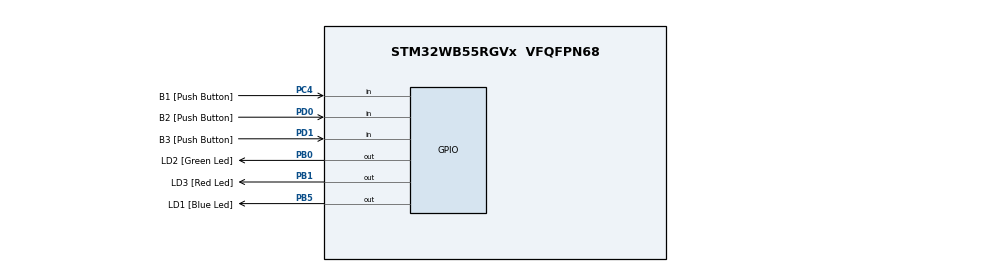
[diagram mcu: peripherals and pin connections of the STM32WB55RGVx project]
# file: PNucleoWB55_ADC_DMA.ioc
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ADC1.Channel-0\#ChannelRegularConversion=ADC_CHANNEL_VBAT
ADC1.Channel-1\#ChannelRegularConversion=ADC_CHANNEL_TEMPSENSOR
ADC1.Channel-2\#ChannelRegularConversion=ADC_CHANNEL_VREFINT
ADC1.ClockPrescaler=ADC_CLOCK_ASYNC_DIV8
ADC1.ContinuousConvMode=DISABLE
ADC1.DMAContinuousRequests=ENABLE
ADC1.EOCSelection=ADC_EOC_SINGLE_CONV
ADC1.NbrOfConversion=3
ADC1.NbrOfConversionFlag=1
ADC1.OffsetNumber-0\#ChannelRegularConversion=ADC_OFFSET_NONE
ADC1.OffsetNumber-1\#ChannelRegularConversion=ADC_OFFSET_NONE
ADC1.OffsetNumber-2\#ChannelRegularConversion=ADC_OFFSET_NONE
ADC1.Rank-0\#ChannelRegularConversion=1
ADC1.Rank-1\#ChannelRegularConversion=2
ADC1.Rank-2\#ChannelRegularConversion=3
ADC1.SamplingTime-0\#ChannelRegularConversion=ADC_SAMPLETIME_92CYCLES_5
ADC1.SamplingTime-1\#ChannelRegularConversion=ADC_SAMPLETIME_247CYCLES_5
ADC1.SamplingTime-2\#ChannelRegularConversion=ADC_SAMPLETIME_92CYCLES_5
ADC1.master=1
Dma.ADC1.0.Direction=DMA_PERIPH_TO_MEMORY
Dma.ADC1.0.EventEnable=DISABLE
Dma.ADC1.0.Instance=DMA1_Channel1
Dma.ADC1.0.MemDataAlignment=DMA_MDATAALIGN_HALFWORD
Dma.ADC1.0.MemInc=DMA_MINC_ENABLE
Dma.ADC1.0.Mode=DMA_NORMAL
Dma.ADC1.0.PeriphDataAlignment=DMA_PDATAALIGN_HALFWORD
Dma.ADC1.0.PeriphInc=DMA_PINC_DISABLE
Dma.ADC1.0.Polarity=HAL_DMAMUX_REQ_GEN_RISING
Dma.ADC1.0.Priority=DMA_PRIORITY_LOW
Dma.ADC1.0.RequestNumber=1
Dma.ADC1.0.SignalID=NONE
Dma.ADC1.0.SyncEnable=DISABLE
Dma.ADC1.0.SyncPolarity=HAL_DMAMUX_SYNC_NO_EVENT
Dma.ADC1.0.SyncRequestNumber=1
Dma.ADC1.0.SyncSignalID=NONE
Dma.Request0=ADC1
Mcu.Family=STM32WB
Mcu.Name=STM32WB55RGVx
Mcu.Package=VFQFPN68
NVIC.ADC1_IRQn=true\:0\:0\:false\:false\:true\:true\:true
NVIC.DMA1_Channel1_IRQn=true\:0\:0\:false\:false\:true\:false\:true
NVIC.PriorityGroup=NVIC_PRIORITYGROUP_4
PA13.GPIO_Label=JTMS
PA13.Mode=Trace_Asynchronous_SW
PA13.Signal=SYS_JTMS-SWDIO
PA14.GPIO_Label=JTCK
PA14.Mode=Trace_Asynchronous_SW
PA14.Signal=SYS_JTCK-SWCLK
PB0.GPIO_Label=LD2 [Green Led]
PB0.Signal=GPIO_Output
PB1.GPIO_Label=LD3 [Red Led]
PB1.Signal=GPIO_Output
PB3.GPIO_Label=JTDO
PB3.Mode=Trace_Asynchronous_SW
PB3.Signal=SYS_JTDO-SWO
PB5.GPIO_Label=LD1 [Blue Led]
PB5.Signal=GPIO_Output
PC13.Mode=SYS_WakeUp1
PC13.Signal=SYS_WKUP2
PC4.GPIO_Label=B1 [Push Button]
PC4.Signal=GPIO_Input
PD0.GPIO_Label=B2 [Push Button]
PD0.Signal=GPIO_Input
PD1.GPIO_Label=B3 [Push Button]
PD1.Signal=GPIO_Input
ProjectManager.HeapSize=0x200
ProjectManager.StackSize=0x400
ProjectManager.TargetToolchain=STM32CubeIDE
RCC.ADCFreq_Value=48000000
RCC.AHB2CLKDivider=RCC_SYSCLK_DIV2
RCC.AHBFreq_Value=64000000
RCC.APB1Freq_Value=64000000
RCC.APB1TimFreq_Value=64000000
RCC.APB2Freq_Value=64000000
RCC.APB2TimFreq_Value=64000000
RCC.APB3Freq_Value=16000000
RCC.CortexFreq_Value=64000000
RCC.HCLKFreq_Value=64000000
RCC.HSE_VALUE=32000000
RCC.HSI48_VALUE=48000000
RCC.HSI_VALUE=16000000
RCC.LSE_VALUE=32768
RCC.PLLN=32
RCC.PLLSAI1N=24
RCC.SMPSCLockSelectionVirtual=RCC_SMPSCLKSOURCE_HSI
RCC.SMPSCLockSelectionVirtualVirtual=RCC_SMPSCLKSOURCE_HSI
RCC.SYSCLKFreq_VALUE=64000000
RCC.SYSCLKSource=RCC_SYSCLKSOURCE_PLLCLK
RCC.USBFreq_Value=48000000
RCC.VCOOutputFreq_Value=128000000
VP_ADC1_TempSens_Input.Mode=IN-TempSens
VP_ADC1_Vbat_Input.Mode=IN-Vbat
VP_ADC1_Vref_Input.Mode=IN-Vrefint
board=P-NUCLEO-WB55-Nucleo

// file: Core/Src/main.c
/* USER CODE BEGIN Header */
/**
  ******************************************************************************
  * @file           : main.c
  * @brief          : Main program body
  ******************************************************************************
  * @attention
  *
  * <h2><center>&copy; Copyright (c) 2020 STMicroelectronics.
  * All rights reserved.</center></h2>
  *
  * This software component is licensed by ST under BSD 3-Clause license,
  * the "License"; You may not use this file except in compliance with the
  * License. You may obtain a copy of the License at:
  *                        opensource.org/licenses/BSD-3-Clause
  *
  ******************************************************************************
  */
/* USER CODE END Header */

#include "main.h"

/* USER CODE BEGIN Includes */
#include <stdbool.h>

/* USER CODE END Includes */

/* USER CODE BEGIN PD */
#define SIZE_BUFFER 	3

/* USER CODE END PD */

ADC_HandleTypeDef hadc1;
DMA_HandleTypeDef hdma_adc1;

/* USER CODE BEGIN PV */
static __IO uint16_t adcSample[SIZE_BUFFER];
static __IO bool adcConvDone = false;
/* USER CODE END PV */

void SystemClock_Config(void);
static void MX_GPIO_Init(void);
static void MX_DMA_Init(void);
static void MX_ADC1_Init(void);

int main(void)
{

  /* MCU Configuration--------------------------------------------------------*/

  /* Reset of all peripherals, Initializes the Flash interface and the Systick. */
  HAL_Init();

  /* Configure the system clock */
  SystemClock_Config();

  /* Initialize all configured peripherals */
  MX_GPIO_Init();
  MX_DMA_Init();
  MX_ADC1_Init();
  /* USER CODE BEGIN 2 */

  if (HAL_ADC_Start_DMA(&hadc1, (uint32_t *)adcSample, SIZE_BUFFER) != HAL_OK)
  {
  	Error_Handler();
  }

  /* USER CODE END 2 */

  /* Infinite loop */
  while (1)
  {

    /* USER CODE BEGIN 3 */
  	if (adcConvDone)
  	{
  	  if (HAL_ADC_Start_DMA(&hadc1, (uint32_t *)adcSample, SIZE_BUFFER) != HAL_OK)
  	  {
  	  	Error_Handler();
  	  }
  		adcConvDone = false;
  	}
  }
  /* USER CODE END 3 */
}

void SystemClock_Config(void)
{
  RCC_OscInitTypeDef RCC_OscInitStruct = {0};
  RCC_ClkInitTypeDef RCC_ClkInitStruct = {0};
  RCC_PeriphCLKInitTypeDef PeriphClkInitStruct = {0};

  /** Configure the main internal regulator output voltage
  */
  __HAL_PWR_VOLTAGESCALING_CONFIG(PWR_REGULATOR_VOLTAGE_SCALE1);
  /** Initializes the CPU, AHB and APB busses clocks
  */
  RCC_OscInitStruct.OscillatorType = RCC_OSCILLATORTYPE_HSI|RCC_OSCILLATORTYPE_MSI;
  RCC_OscInitStruct.HSIState = RCC_HSI_ON;
  RCC_OscInitStruct.MSIState = RCC_MSI_ON;
  RCC_OscInitStruct.HSICalibrationValue = RCC_HSICALIBRATION_DEFAULT;
  RCC_OscInitStruct.MSICalibrationValue = RCC_MSICALIBRATION_DEFAULT;
  RCC_OscInitStruct.MSIClockRange = RCC_MSIRANGE_6;
  RCC_OscInitStruct.PLL.PLLState = RCC_PLL_ON;
  RCC_OscInitStruct.PLL.PLLSource = RCC_PLLSOURCE_MSI;
  RCC_OscInitStruct.PLL.PLLM = RCC_PLLM_DIV1;
  RCC_OscInitStruct.PLL.PLLN = 32;
  RCC_OscInitStruct.PLL.PLLP = RCC_PLLP_DIV2;
  RCC_OscInitStruct.PLL.PLLR = RCC_PLLR_DIV2;
  RCC_OscInitStruct.PLL.PLLQ = RCC_PLLQ_DIV2;
  if (HAL_RCC_OscConfig(&RCC_OscInitStruct) != HAL_OK)
  {
    Error_Handler();
  }
  /** Configure the SYSCLKSource, HCLK, PCLK1 and PCLK2 clocks dividers
  */
  RCC_ClkInitStruct.ClockType = RCC_CLOCKTYPE_HCLK4|RCC_CLOCKTYPE_HCLK2
                              |RCC_CLOCKTYPE_HCLK|RCC_CLOCKTYPE_SYSCLK
                              |RCC_CLOCKTYPE_PCLK1|RCC_CLOCKTYPE_PCLK2;
  RCC_ClkInitStruct.SYSCLKSource = RCC_SYSCLKSOURCE_PLLCLK;
  RCC_ClkInitStruct.AHBCLKDivider = RCC_SYSCLK_DIV1;
  RCC_ClkInitStruct.APB1CLKDivider = RCC_HCLK_DIV1;
  RCC_ClkInitStruct.APB2CLKDivider = RCC_HCLK_DIV1;
  RCC_ClkInitStruct.AHBCLK2Divider = RCC_SYSCLK_DIV2;
  RCC_ClkInitStruct.AHBCLK4Divider = RCC_SYSCLK_DIV1;

  if (HAL_RCC_ClockConfig(&RCC_ClkInitStruct, FLASH_LATENCY_3) != HAL_OK)
  {
    Error_Handler();
  }
  /** Initializes the peripherals clocks
  */
  PeriphClkInitStruct.PeriphClockSelection = RCC_PERIPHCLK_SMPS|RCC_PERIPHCLK_ADC;
  PeriphClkInitStruct.PLLSAI1.PLLN = 24;
  PeriphClkInitStruct.PLLSAI1.PLLP = RCC_PLLP_DIV2;
  PeriphClkInitStruct.PLLSAI1.PLLQ = RCC_PLLQ_DIV2;
  PeriphClkInitStruct.PLLSAI1.PLLR = RCC_PLLR_DIV2;
  PeriphClkInitStruct.PLLSAI1.PLLSAI1ClockOut = RCC_PLLSAI1_ADCCLK;
  PeriphClkInitStruct.AdcClockSelection = RCC_ADCCLKSOURCE_PLLSAI1;
  PeriphClkInitStruct.SmpsClockSelection = RCC_SMPSCLKSOURCE_HSI;
  PeriphClkInitStruct.SmpsDivSelection = RCC_SMPSCLKDIV_RANGE1;

  if (HAL_RCCEx_PeriphCLKConfig(&PeriphClkInitStruct) != HAL_OK)
  {
    Error_Handler();
  }
}

static void MX_ADC1_Init(void)
{

  ADC_ChannelConfTypeDef sConfig = {0};

  /** Common config
  */
  hadc1.Instance = ADC1;
  hadc1.Init.ClockPrescaler = ADC_CLOCK_ASYNC_DIV8;
  hadc1.Init.Resolution = ADC_RESOLUTION_12B;
  hadc1.Init.DataAlign = ADC_DATAALIGN_RIGHT;
  hadc1.Init.ScanConvMode = ADC_SCAN_ENABLE;
  hadc1.Init.EOCSelection = ADC_EOC_SINGLE_CONV;
  hadc1.Init.LowPowerAutoWait = DISABLE;
  hadc1.Init.ContinuousConvMode = DISABLE;
  hadc1.Init.NbrOfConversion = 3;
  hadc1.Init.DiscontinuousConvMode = DISABLE;
  hadc1.Init.NbrOfDiscConversion = 1;
  hadc1.Init.ExternalTrigConv = ADC_SOFTWARE_START;
  hadc1.Init.ExternalTrigConvEdge = ADC_EXTERNALTRIGCONVEDGE_NONE;
  hadc1.Init.DMAContinuousRequests = ENABLE;
  hadc1.Init.Overrun = ADC_OVR_DATA_PRESERVED;
  hadc1.Init.OversamplingMode = DISABLE;
  if (HAL_ADC_Init(&hadc1) != HAL_OK)
  {
    Error_Handler();
  }
  /** Configure Regular Channel
  */
  sConfig.Channel = ADC_CHANNEL_VBAT;
  sConfig.Rank = ADC_REGULAR_RANK_1;
  sConfig.SamplingTime = ADC_SAMPLETIME_92CYCLES_5;
  sConfig.SingleDiff = ADC_SINGLE_ENDED;
  sConfig.OffsetNumber = ADC_OFFSET_NONE;
  sConfig.Offset = 0;
  if (HAL_ADC_ConfigChannel(&hadc1, &sConfig) != HAL_OK)
  {
    Error_Handler();
  }
  /** Configure Regular Channel
  */
  sConfig.Channel = ADC_CHANNEL_TEMPSENSOR;
  sConfig.Rank = ADC_REGULAR_RANK_2;
  sConfig.SamplingTime = ADC_SAMPLETIME_247CYCLES_5;
  if (HAL_ADC_ConfigChannel(&hadc1, &sConfig) != HAL_OK)
  {
    Error_Handler();
  }
  /** Configure Regular Channel
  */
  sConfig.Channel = ADC_CHANNEL_VREFINT;
  sConfig.Rank = ADC_REGULAR_RANK_3;
  sConfig.SamplingTime = ADC_SAMPLETIME_92CYCLES_5;
  if (HAL_ADC_ConfigChannel(&hadc1, &sConfig) != HAL_OK)
  {
    Error_Handler();
  }
  /* USER CODE BEGIN ADC1_Init 2 */

  if (HAL_ADCEx_Calibration_Start(&hadc1, ADC_SINGLE_ENDED) != HAL_OK)
  {
    Error_Handler();
  }

  /* USER CODE END ADC1_Init 2 */

}

static void MX_DMA_Init(void)
{

  /* DMA controller clock enable */
  __HAL_RCC_DMAMUX1_CLK_ENABLE();
  __HAL_RCC_DMA1_CLK_ENABLE();

  /* DMA interrupt init */
  /* DMA1_Channel1_IRQn interrupt configuration */
  HAL_NVIC_SetPriority(DMA1_Channel1_IRQn, 0, 0);
  HAL_NVIC_EnableIRQ(DMA1_Channel1_IRQn);

}

static void MX_GPIO_Init(void)
{
  GPIO_InitTypeDef GPIO_InitStruct = {0};

  /* GPIO Ports Clock Enable */
  __HAL_RCC_GPIOC_CLK_ENABLE();
  __HAL_RCC_GPIOB_CLK_ENABLE();
  __HAL_RCC_GPIOA_CLK_ENABLE();
  __HAL_RCC_GPIOD_CLK_ENABLE();

  /*Configure GPIO pin Output Level */
  HAL_GPIO_WritePin(GPIOB, LD2_Pin|LD3_Pin|LD1_Pin, GPIO_PIN_RESET);

  /*Configure GPIO pin : B1_Pin */
  GPIO_InitStruct.Pin = B1_Pin;
  GPIO_InitStruct.Mode = GPIO_MODE_INPUT;
  GPIO_InitStruct.Pull = GPIO_NOPULL;
  HAL_GPIO_Init(B1_GPIO_Port, &GPIO_InitStruct);

  /*Configure GPIO pins : LD2_Pin LD3_Pin LD1_Pin */
  GPIO_InitStruct.Pin = LD2_Pin|LD3_Pin|LD1_Pin;
  GPIO_InitStruct.Mode = GPIO_MODE_OUTPUT_PP;
  GPIO_InitStruct.Pull = GPIO_NOPULL;
  GPIO_InitStruct.Speed = GPIO_SPEED_FREQ_LOW;
  HAL_GPIO_Init(GPIOB, &GPIO_InitStruct);

  /*Configure GPIO pins : B2_Pin B3_Pin */
  GPIO_InitStruct.Pin = B2_Pin|B3_Pin;
  GPIO_InitStruct.Mode = GPIO_MODE_INPUT;
  GPIO_InitStruct.Pull = GPIO_NOPULL;
  HAL_GPIO_Init(GPIOD, &GPIO_InitStruct);

}

/* USER CODE BEGIN 4 */
/**
  * @brief  Conversion complete callback in non-blocking mode.
  * @param hadc ADC handle
  * @retval None
  */
void HAL_ADC_ConvCpltCallback(ADC_HandleTypeDef *hadc)
{
	adcConvDone = true;
}

/* USER CODE END 4 */

void Error_Handler(void)
{
}

/************************ (C) COPYRIGHT STMicroelectronics *****END OF FILE****/
